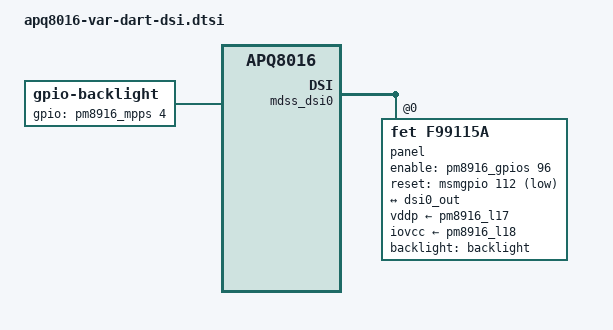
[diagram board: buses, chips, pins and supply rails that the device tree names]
/ {
	backlight: backlight {
		compatible = "gpio-backlight";
		gpios = <&pm8916_mpps 4 GPIO_ACTIVE_HIGH>;
		default-on;
	};
};


&mdss_dsi0 {
    #address-cells = <1>;
    #size-cells = <0>;
 	status = "ok";
	panel:panel@0 {
		reg = <0>;
		status = "ok";
		compatible = "fet,f99115a";
		backlight = <&backlight>;

		vddp-supply = <&pm8916_l17>;
		iovcc-supply = <&pm8916_l18>;

		enable-gpios = <&pm8916_gpios 96 GPIO_ACTIVE_HIGH>;
		reset-gpios = <&msmgpio 112 GPIO_ACTIVE_LOW>;
		//power ic


		port {
			panel_in: endpoint {
				remote-endpoint = <&dsi0_out>;
			};
		};
	};

};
